# AVR32LA20 register map
Vendor: Atmel; File version: 1.0
CPU: other r0p0, little endian, no MPU, no FPU, 4 interrupt priority bits
Registers are 8-bit, read-write, reset 0x0 unless marked. A register's access mark holds for its fields unless they carry their own. Offsets are from the block's base; [hi:lo] are bit positions; {n}, {i} and the like mark numbered series; 'fields as' and 'values as' point back to an identical list.

## EVSYS — Event System
Base 0x00800200
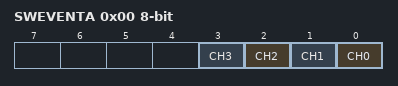
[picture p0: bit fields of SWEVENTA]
0x00 SWEVENTA wo — Software Event A
  [n] CH{n} (n=0..3) — Channel {n} Select
{0x10+i} CHANNEL{i} (i=0..3) — Multiplexer Channel {i}
  [7:0] CHANNEL — Channel Generator Select
    0=OFF; 1=UPDI_SYNCH (UPDI SYNCH character); 6=RTC_OVF (Real Time Counter overflow); 7=RTC_CMP (Real Time Counter compare); 8=RTC_EVGEN0 (Selectable prescaled RTC Event 0); 9=RTC_EVGEN1 (Selectable prescaled RTC Event 1); {v}=CCL_LUT{v-16} (Configurable Custom Logic LUT{v-16}) (v=16..19); 32=AC0_OUT (Analog Comparator 0 out); 36=ADC0_RES (ADC 0 Result Ready); 37=ADC0_SAMP (ADC 0 Sample Ready); 38=ADC0_WCMP (ADC 0 Window Compare); 64=PORTA_EVGEN0 (Port A Event 0); 65=PORTA_EVGEN1 (Port A Event 1); 68=PORTC_EVGEN0 (Port C Event 0); 69=PORTC_EVGEN1 (Port C Event 1); 70=PORTD_EVGEN0 (Port D Event 0); 71=PORTD_EVGEN1 (Port D Event 1); 74=PORTF_EVGEN0 (Port F Event 0); 75=PORTF_EVGEN1 (Port F Event 1); 96=USART0_XCK; 104=SPI0_SCK; 128=TCE0_OVF (Timer/Counter E0 overflow); 132=TCE0_CMP0 (Timer/Counter E0 compare 0); 133=TCE0_CMP1 (Timer/Counter E0 compare 1); 134=TCE0_CMP2 (Timer/Counter E0 compare 2); 160=TCB0_CAPT (Timer/Counter B0 capture); 161=TCB0_OVF (Timer/Counter B0 overflow); 162=TCB1_CAPT (Timer/Counter B1 capture); 163=TCB1_OVF (Timer/Counter B1 overflow)
0x20 USERCCLLUT0A — User 0 - CCL LUT0 Event A
  [7:0] USER — User channel select
    0=OFF; {v}=CHANNEL{v-1} (Connect user to event channel {v-1}) (v=1..4)
0x21 USERCCLLUT0B — User 1 - CCL LUT0 Event B
  fields as USERCCLLUT0A
0x22 USERCCLLUT1A — User 2 - CCL LUT1 Event A
  fields as USERCCLLUT0A
0x23 USERCCLLUT1B — User 3 - CCL LUT1 Event B
  fields as USERCCLLUT0A
0x24 USERAC0SAMPLE — User 4 - AC0
  fields as USERCCLLUT0A
0x25 USERADC0START — User 5 - ADC0
  fields as USERCCLLUT0A
0x26 USEREVSYSEVOUTA — User 6 - EVOUTA
  fields as USERCCLLUT0A
0x27 USEREVSYSEVOUTC — User 7 - EVOUTC
  fields as USERCCLLUT0A
0x28 USEREVSYSEVOUTD — User 8 - EVOUTD
  fields as USERCCLLUT0A
0x29 USEREVSYSEVOUTF — User 9 - EVOUTF
  fields as USERCCLLUT0A
0x2A USERUSART0RXD — User 10 - USART0 RxD Event Input
  fields as USERCCLLUT0A
0x2B USERTCE0CNTA — User 11 - TCE0 Count A
  fields as USERCCLLUT0A
0x2C USERTCE0CNTB — User 12 - TCE0 Count B
  fields as USERCCLLUT0A
0x2D USERTCB0CAPT — User 13 - TCB0 Capture
  fields as USERCCLLUT0A
0x2E USERTCB0COUNT — User 14 - TCB0 Count
  fields as USERCCLLUT0A
0x2F USERTCB1CAPT — User 15 - TCB1 Capture
  fields as USERCCLLUT0A
0x30 USERTCB1COUNT — User 16 - TCB1 Count
  fields as USERCCLLUT0A

## GPR — General Purpose Registers
Base 0x0080001C
{0x0+i} GPR{i} (i=0..3) — General Purpose Register {i}

## LOCK — Lockbits
Base 0x00801040
0x00 KEY 32-bit (reset mask 0xFF) — Lock Key Bits
  [31:0] KEY — Lock Key
    0x5CC5C55C=NOLOCK (No locks); 0xA33A3AA3=RWLOCK (Read and write lock)

## NVMCTRL — Non-volatile Memory Controller
Base 0x00801000
0x00 CTRLA — Control A
  [6:0] CMD — Command
    0=NOCMD (No Command); 1=NOOP (No Operation); 4=FLPW (Flash Page Write); 5=FLPERW (Flash Page Erase and Write); 8=FLPER (Flash Page Erase); 9=FLMPER2 (Flash 2-page erase enable); 10=FLMPER4 (Flash 4-page erase enable); 11=FLMPER8 (Flash 8-page erase enable); 12=FLMPER16 (Flash 16-page erase enable); 13=FLMPER32 (Flash 32-page erase enable); 15=FLPBCLR (Flash Page Buffer Clear); 20=EEPW (EEPROM Page Write); 21=EEPERW (EEPROM Page Erase and Write); 23=EEPER (EEPROM Page Erase); 31=EEPBCLR (EEPROM Page Buffer Clear); 32=CHER (Chip Erase Command (UPDI only)); 48=EECHER (EEPROM Erase Command (UPDI only))
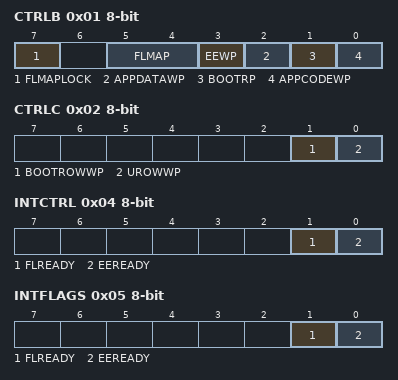
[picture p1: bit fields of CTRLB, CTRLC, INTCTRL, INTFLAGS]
0x01 CTRLB — Control B
  [7] FLMAPLOCK — Flash Mapping Lock
  [5:4] FLMAP — Flash Mapping in Data space
    0=SECTION0 (Flash section 0, 0 - 32KB); 1=SECTION1 (Flash section 1, 32 - 64KB); 2=SECTION2 (Flash section 2, 64 - 96KB); 3=SECTION3 (Flash section 3, 96 - 128KB)
  [3] EEWP — EEPROM Write Protect
  [2] APPDATAWP — Application Data Write Protect
  [1] BOOTRP — Boot Read Protect
  [0] APPCODEWP — Application Code Write Protect
0x02 CTRLC — Control C
  [1] BOOTROWWP — Boot Row Write Protect
  [0] UROWWP — User Row Write Protect
0x04 INTCTRL — Interrupt Control
  [1] FLREADY — Flash Ready
  [0] EEREADY — EEPROM Ready
0x05 INTFLAGS — Interrupt Flags
  [1] FLREADY — Flash Ready
  [0] EEREADY — EEPROM Ready
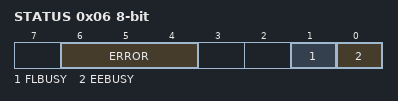
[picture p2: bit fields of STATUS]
0x06 STATUS
  [6:4] ERROR — Write error
    0=NOERROR; 2=WRITEPROTECT (Attempt to program write protected area); 3=CMDCOLLISION (Selecting new write command while write command already seleted); 4=WRONGSECTION (Address cannot be written with selected command)
  [1] FLBUSY ro — Flash busy
  [0] EEBUSY ro — EEPROM busy
0x08 DATA 16-bit (reset mask 0xFF)
0x0C ADDR 32-bit (reset mask 0xFF) — Address
  [23:0] ADDR
